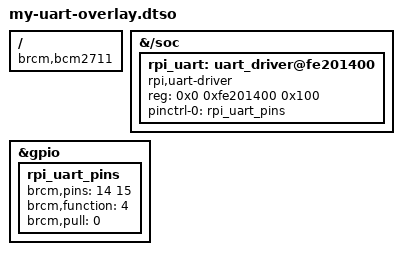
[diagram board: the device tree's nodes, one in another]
/dts-v1/;
/plugin/;

/ {
    compatible = "brcm,bcm2711";

    fragment@0 {
        target-path = "/soc";
        __overlay__ {
            
			#address-cells = <2>;
			#size-cells = <1>;

            rpi_uart: uart_driver@fe201400 {
                compatible = "rpi,uart-driver";
                reg = <0x0 0xfe201400 0x100>;     /* UART0 base address */
				pinctrl-names = "default";
                pinctrl-0 = <&rpi_uart_pins>;
				status = "okay";
            };
        };
    };

    fragment@1 {
        target = <&gpio>;
        __overlay__ {
            rpi_uart_pins: rpi_uart_pins {
                brcm,pins = <14 15>;
                brcm,function = <4>;      /* ALT0 = UART0 */
                brcm,pull = <0>;
            };
        };
    };
};


